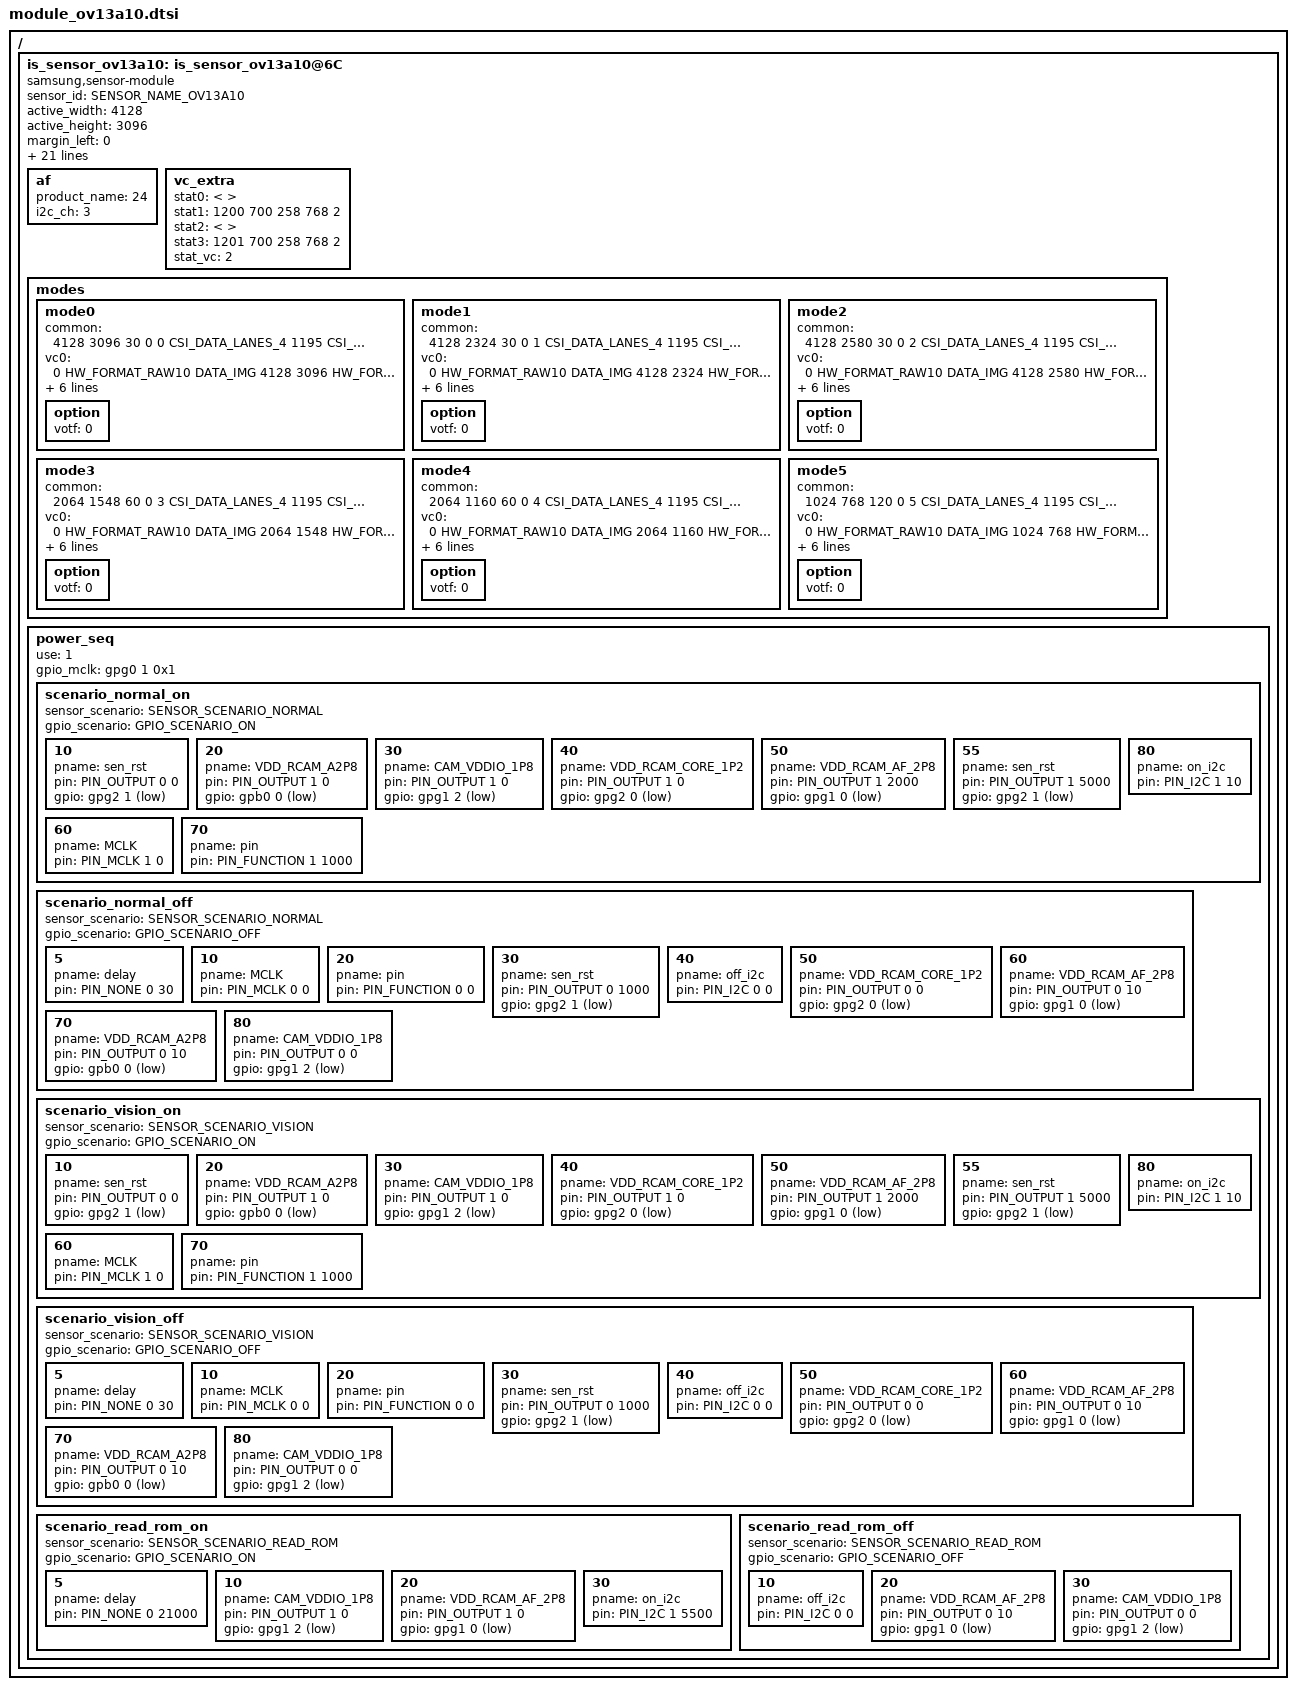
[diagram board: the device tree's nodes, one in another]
/*
 * SAMSUNG EXYNOSxxxx board camera device tree source
 *
 * Copyright (c) 2024 Samsung Electronics Co., Ltd.
 *		http://www.samsung.com
 *
 * This program is free software; you can redistribute it and/or modify
 * it under the terms of the GNU General Public License version 2 as
 * published by the Free Software Foundation.
 */

#include <dt-bindings/camera/exynos_is_dt.h>

/ {
	fragment@camera {
		target-path = "/";
		__overlay__ {
			is_sensor_ov13a10: is_sensor_ov13a10@6C {
				compatible = "samsung,sensor-module";

				/* common */
				sensor_id = <SENSOR_NAME_OV13A10>;
				active_width = <4128>;
				active_height = <3096>;
				margin_left = <0>;
				margin_right = <0>;
				margin_top = <0>;
				margin_bottom = <0>;
				max_framerate = <120>;
				bitwidth = <10>;
				use_retention_mode = <SENSOR_RETENTION_UNSUPPORTED>;
				sensor_maker = "OMNIVISION";
				sensor_name = "OV13A10";
				setfile_name = "setfile_ov13a10.bin";
				pinning_setfile;
				status = "okay";

				/* board */
				pinctrl-names = "pin0", "pin1", "release";
				pinctrl-0 = <&sensor_mclk0_out>;
				pinctrl-1 = <&sensor_mclk0_fn>;
				pinctrl-2 = <>;

				position = <0>; /* Rear:0. Front:1, Tele:2, UW:4 */
				id = <0>; /* is_sensor id */
				mclk_ch = <0>;
				mclk_freq = <19200>;
				sensor_i2c_ch = <0>; /* SENSOR_CONTROL_I2C2 */

				/* vendor */
				rom_id = <0>;
				rom_cal_index = <0>;

				/* peri */
				af {
					product_name = <24>; /* ACTUATOR_NAME_DW9808 */
					i2c_ch = <3>; /* SENSOR_CONTROL_I2C3 */
				};

				vc_extra {
					/* ex) statX = <stat_type, sensor_mode, max_width, max_height, max_element> */
					stat0 = </* not available */>; /* VC_BUF_DATA_TYPE_SENSOR_STAT1 */
					stat1 = </*VC_STAT_TYPE_PDP_4_1_PDAF_STAT0*/ 1200 /*VC_SENSOR_MODE_ULTRA_PD_TAIL*/ 700 258 768 2>; /* VC_BUF_DATA_TYPE_GENERAL_STAT1 */
					stat2 = </* not available */>; /* VC_BUF_DATA_TYPE_SENSOR_STAT2 */
					stat3 = </*VC_STAT_TYPE_PDP_4_1_PDAF_STAT1*/ 1201 /*VC_SENSOR_MODE_ULTRA_PD_TAIL*/ 700 258 768 2>; /* VC_BUF_DATA_TYPE_GENERAL_STAT2 */
					stat_vc = <2>; /* STAT out VC after CSIS link */
				};

				/* sensor modes */
				modes {
						/* common = <width, height, fps, settle, mode, lane, speed, interleave, lrte, pd_mode> */
						/* vcX = <map, hwformat, width, height, hwformat, type, width, height> */
					mode0 {
						common = <4128 3096 30 0 0 CSI_DATA_LANES_4 1195 CSI_MODE_VC_DT LRTE_DISABLE PD_MSPD_TAIL EX_NONE>;
						vc0 = </* in */ 0 HW_FORMAT_RAW10 DATA_IMG 4128 3096    /* out */ HW_FORMAT_RAW10 VC_NOTHING 4128 3096>;
						vc1 = </* in */ 2 HW_FORMAT_UNKNOWN DATA_NONE 0 0        /* out */ HW_FORMAT_UNKNOWN VC_NOTHING 0 0>;
						vc2 = </* in */ 1 HW_FORMAT_RAW10_POTF_PACK DATA_HPD 256 768      /* out */ HW_FORMAT_UNKNOWN VC_NOTHING 0 0>;
						vc3 = </* in */ 3 HW_FORMAT_UNKNOWN DATA_NONE 0 0        /* out */ HW_FORMAT_UNKNOWN VC_NOTHING 0 0>;
						option { votf = <0>; };
					};

					mode1 {
						common = <4128 2324 30 0 1 CSI_DATA_LANES_4 1195 CSI_MODE_VC_DT LRTE_DISABLE PD_MSPD_TAIL EX_NONE>;
						vc0 = </* in */ 0 HW_FORMAT_RAW10 DATA_IMG 4128 2324    /* out */ HW_FORMAT_RAW10 VC_NOTHING 4128 2324>;
						vc1 = </* in */ 2 HW_FORMAT_UNKNOWN DATA_NONE 0 0        /* out */ HW_FORMAT_UNKNOWN VC_NOTHING 0 0>;
						vc2 = </* in */ 1 HW_FORMAT_RAW10_POTF_PACK DATA_HPD 256 576    /* out */ HW_FORMAT_UNKNOWN VC_NOTHING 0 0>;
						vc3 = </* in */ 3 HW_FORMAT_UNKNOWN DATA_NONE 0 0        /* out */ HW_FORMAT_UNKNOWN VC_NOTHING 0 0>;
						option { votf = <0>; };
					};

					mode2 {
						common = <4128 2580 30 0 2 CSI_DATA_LANES_4 1195 CSI_MODE_VC_DT LRTE_DISABLE PD_MSPD_TAIL EX_NONE>;
						vc0 = </* in */ 0 HW_FORMAT_RAW10 DATA_IMG 4128 2580    /* out */ HW_FORMAT_RAW10 VC_NOTHING 4128 2580>;
						vc1 = </* in */ 2 HW_FORMAT_UNKNOWN DATA_NONE 0 0        /* out */ HW_FORMAT_UNKNOWN VC_NOTHING 0 0>;
						vc2 = </* in */ 1 HW_FORMAT_RAW10_POTF_PACK DATA_HPD 256 640    /* out */ HW_FORMAT_UNKNOWN VC_NOTHING 0 0>;
						vc3 = </* in */ 3 HW_FORMAT_UNKNOWN DATA_NONE 0 0        /* out */ HW_FORMAT_UNKNOWN VC_NOTHING 0 0>;
						option { votf = <0>; };
					};

					mode3 {
						common = <2064 1548 60 0 3 CSI_DATA_LANES_4 1195 CSI_MODE_VC_ONLY LRTE_DISABLE PD_NONE EX_NONE>;
						vc0 = </* in */ 0 HW_FORMAT_RAW10 DATA_IMG 2064 1548    /* out */ HW_FORMAT_RAW10 VC_NOTHING 2064 1548>;
						vc1 = </* in */ 2 HW_FORMAT_UNKNOWN DATA_NONE 0 0        /* out */ HW_FORMAT_UNKNOWN VC_NOTHING 0 0>;
						vc2 = </* in */ 1 HW_FORMAT_UNKNOWN DATA_NONE 0 0        /* out */ HW_FORMAT_UNKNOWN VC_NOTHING 0 0>;
						vc3 = </* in */ 3 HW_FORMAT_UNKNOWN DATA_NONE 0 0        /* out */ HW_FORMAT_UNKNOWN VC_NOTHING 0 0>;
						option { votf = <0>; };
					};

					mode4 {
						common = <2064 1160 60 0 4 CSI_DATA_LANES_4 1195 CSI_MODE_VC_ONLY LRTE_DISABLE PD_NONE EX_NONE>;
						vc0 = </* in */ 0 HW_FORMAT_RAW10 DATA_IMG 2064 1160    /* out */ HW_FORMAT_RAW10 VC_NOTHING 2064 1160>;
						vc1 = </* in */ 2 HW_FORMAT_UNKNOWN DATA_NONE 0 0        /* out */ HW_FORMAT_UNKNOWN VC_NOTHING 0 0>;
						vc2 = </* in */ 1 HW_FORMAT_UNKNOWN DATA_NONE 0 0        /* out */ HW_FORMAT_UNKNOWN VC_NOTHING 0 0>;
						vc3 = </* in */ 3 HW_FORMAT_UNKNOWN DATA_NONE 0 0        /* out */ HW_FORMAT_UNKNOWN VC_NOTHING 0 0>;
						option { votf = <0>; };
					};

					mode5 {
						common = <1024 768 120 0 5 CSI_DATA_LANES_4 1195 CSI_MODE_VC_ONLY LRTE_DISABLE PD_NONE EX_NONE>;
						vc0 = </* in */ 0 HW_FORMAT_RAW10 DATA_IMG 1024 768    /* out */ HW_FORMAT_RAW10 VC_NOTHING 1024 768>;
						vc1 = </* in */ 2 HW_FORMAT_UNKNOWN DATA_NONE 0 0        /* out */ HW_FORMAT_UNKNOWN VC_NOTHING 0 0>;
						vc2 = </* in */ 1 HW_FORMAT_UNKNOWN DATA_NONE 0 0        /* out */ HW_FORMAT_UNKNOWN VC_NOTHING 0 0>;
						vc3 = </* in */ 3 HW_FORMAT_UNKNOWN DATA_NONE 0 0        /* out */ HW_FORMAT_UNKNOWN VC_NOTHING 0 0>;
						option { votf = <0>; };
					};
				};

				power_seq {
					use = <1>;
					gpio_mclk = <&gpg0 1 0x1>;
					scenario_normal_on {
						sensor_scenario = <SENSOR_SCENARIO_NORMAL>;
						gpio_scenario = <GPIO_SCENARIO_ON>;

						/* A start node number should be over the 10 for reserved number 0~9. */
						/* pname = "name"; pin = <act value delay voltage>; gpio = <gpx# # 0x1>; */
						10 { pname = "sen_rst"; pin = <PIN_OUTPUT 0 0>; gpio = <&gpg2 1 0x1>; };
						20 { pname = "VDD_RCAM_A2P8"; pin = <PIN_OUTPUT 1 0>; gpio = <&gpb0 0 0x1>; };
						30 { pname = "CAM_VDDIO_1P8"; pin = <PIN_OUTPUT 1 0>; gpio = <&gpg1 2 0x1>; };
						40 { pname = "VDD_RCAM_CORE_1P2"; pin = <PIN_OUTPUT 1 0>; gpio = <&gpg2 0 0x1>; };
						50 { pname = "VDD_RCAM_AF_2P8"; pin = <PIN_OUTPUT 1 2000>; gpio = <&gpg1 0 0x1>; };
						55 { pname = "sen_rst"; pin = <PIN_OUTPUT 1 5000>; gpio = <&gpg2 1 0x1>; };
						60 { pname = "MCLK"; pin = <PIN_MCLK 1 0>; };
						70 { pname = "pin"; pin = <PIN_FUNCTION 1 1000>; };
						80 { pname = "on_i2c"; pin = <PIN_I2C 1 10>; };
					};

					scenario_normal_off {
						sensor_scenario = <SENSOR_SCENARIO_NORMAL>;
						gpio_scenario = <GPIO_SCENARIO_OFF>;

						/* A start node number should be over the 10 for reserved number 0~9. */
						/* pname = "name"; pin = <act value delay voltage>; gpio = <gpx# # 0x1>; */
						5 { pname = "delay"; pin = <PIN_NONE 0 30>; };
						10 { pname = "MCLK"; pin = <PIN_MCLK 0 0>; };
						20 { pname = "pin"; pin = <PIN_FUNCTION 0 0>; };
						30 { pname = "sen_rst"; pin = <PIN_OUTPUT 0 1000>; gpio = <&gpg2 1 0x1>; };
						40 { pname = "off_i2c"; pin = <PIN_I2C 0 0>; };
						50 { pname = "VDD_RCAM_CORE_1P2"; pin = <PIN_OUTPUT 0 0>; gpio = <&gpg2 0 0x1>; };
						60 { pname = "VDD_RCAM_AF_2P8"; pin = <PIN_OUTPUT 0 10>; gpio = <&gpg1 0 0x1>; };
						70 { pname = "VDD_RCAM_A2P8"; pin = <PIN_OUTPUT 0 10>; gpio = <&gpb0 0 0x1>; };
						80 { pname = "CAM_VDDIO_1P8"; pin = <PIN_OUTPUT 0 0>; gpio = <&gpg1 2 0x1>; };
					};

					scenario_vision_on {
						sensor_scenario = <SENSOR_SCENARIO_VISION>;
						gpio_scenario = <GPIO_SCENARIO_ON>;

						/* A start node number should be over the 10 for reserved number 0~9. */
						/* pname = "name"; pin = <act value delay voltage>; gpio = <gpx# # 0x1>; */
						10 { pname = "sen_rst"; pin = <PIN_OUTPUT 0 0>; gpio = <&gpg2 1 0x1>; };
						20 { pname = "VDD_RCAM_A2P8"; pin = <PIN_OUTPUT 1 0>; gpio = <&gpb0 0 0x1>; };
						30 { pname = "CAM_VDDIO_1P8"; pin = <PIN_OUTPUT 1 0>; gpio = <&gpg1 2 0x1>; };
						40 { pname = "VDD_RCAM_CORE_1P2"; pin = <PIN_OUTPUT 1 0>; gpio = <&gpg2 0 0x1>; };
						50 { pname = "VDD_RCAM_AF_2P8"; pin = <PIN_OUTPUT 1 2000>; gpio = <&gpg1 0 0x1>; };
						55 { pname = "sen_rst"; pin = <PIN_OUTPUT 1 5000>; gpio = <&gpg2 1 0x1>; };
						60 { pname = "MCLK"; pin = <PIN_MCLK 1 0>; };
						70 { pname = "pin"; pin = <PIN_FUNCTION 1 1000>; };
						80 { pname = "on_i2c"; pin = <PIN_I2C 1 10>; };
					};

					scenario_vision_off {
						sensor_scenario = <SENSOR_SCENARIO_VISION>;
						gpio_scenario = <GPIO_SCENARIO_OFF>;

						/* A start node number should be over the 10 for reserved number 0~9. */
						/* pname = "name"; pin = <act value delay voltage>; gpio = <gpx# # 0x1>; */
						5 { pname = "delay"; pin = <PIN_NONE 0 30>; };
						10 { pname = "MCLK"; pin = <PIN_MCLK 0 0>; };
						20 { pname = "pin"; pin = <PIN_FUNCTION 0 0>; };
						30 { pname = "sen_rst"; pin = <PIN_OUTPUT 0 1000>; gpio = <&gpg2 1 0x1>; };
						40 { pname = "off_i2c"; pin = <PIN_I2C 0 0>; };
						50 { pname = "VDD_RCAM_CORE_1P2"; pin = <PIN_OUTPUT 0 0>; gpio = <&gpg2 0 0x1>; };
						60 { pname = "VDD_RCAM_AF_2P8"; pin = <PIN_OUTPUT 0 10>; gpio = <&gpg1 0 0x1>; };
						70 { pname = "VDD_RCAM_A2P8"; pin = <PIN_OUTPUT 0 10>; gpio = <&gpb0 0 0x1>; };
						80 { pname = "CAM_VDDIO_1P8"; pin = <PIN_OUTPUT 0 0>; gpio = <&gpg1 2 0x1>; };
					};

					scenario_read_rom_on {
						sensor_scenario = <SENSOR_SCENARIO_READ_ROM>;
						gpio_scenario = <GPIO_SCENARIO_ON>;

						/* A start node number should be over the 10 for reserved number 0~9. */
						/* pname = "name"; pin = <act value delay voltage>; gpio = <gpx# # 0x1>; */
						5 { pname = "delay"; pin = <PIN_NONE 0 21000>; };
						10 { pname = "CAM_VDDIO_1P8"; pin = <PIN_OUTPUT 1 0>; gpio = <&gpg1 2 0x1>; };
						20 { pname = "VDD_RCAM_AF_2P8"; pin = <PIN_OUTPUT 1 0>; gpio = <&gpg1 0 0x1>; };
						30 { pname = "on_i2c"; pin = <PIN_I2C 1 5500>; };
					};

					scenario_read_rom_off {
						sensor_scenario = <SENSOR_SCENARIO_READ_ROM>;
						gpio_scenario = <GPIO_SCENARIO_OFF>;

						/* A start node number should be over the 10 for reserved number 0~9. */
						/* pname = "name"; pin = <act value delay voltage>; gpio = <gpx# # 0x1>; */
						10 { pname = "off_i2c"; pin = <PIN_I2C 0 0>; };
						20 { pname = "VDD_RCAM_AF_2P8"; pin = <PIN_OUTPUT 0 10>; gpio = <&gpg1 0 0x1>; };
						30 { pname = "CAM_VDDIO_1P8"; pin = <PIN_OUTPUT 0 0>; gpio = <&gpg1 2 0x1>; };
					};
				};
			};
		}; /* end of __overlay__ */
	}; /* end of fragment */
}; /* end of root */
